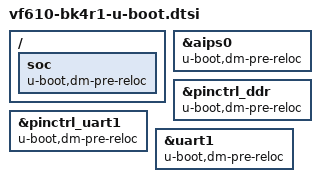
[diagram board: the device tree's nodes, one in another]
// SPDX-License-Identifier: (GPL-2.0+ OR MIT)
/*
 * Copyright 2019
 * Lukasz Majewski, DENX Software Engineering, lukma@denx.de
 */

/ {
	soc {
		u-boot,dm-pre-reloc;
	};
};

&aips0 {
	u-boot,dm-pre-reloc;
};

&pinctrl_ddr {
	u-boot,dm-pre-reloc;
};

&pinctrl_uart1 {
	u-boot,dm-pre-reloc;
};

&uart1 {
	u-boot,dm-pre-reloc;
};
